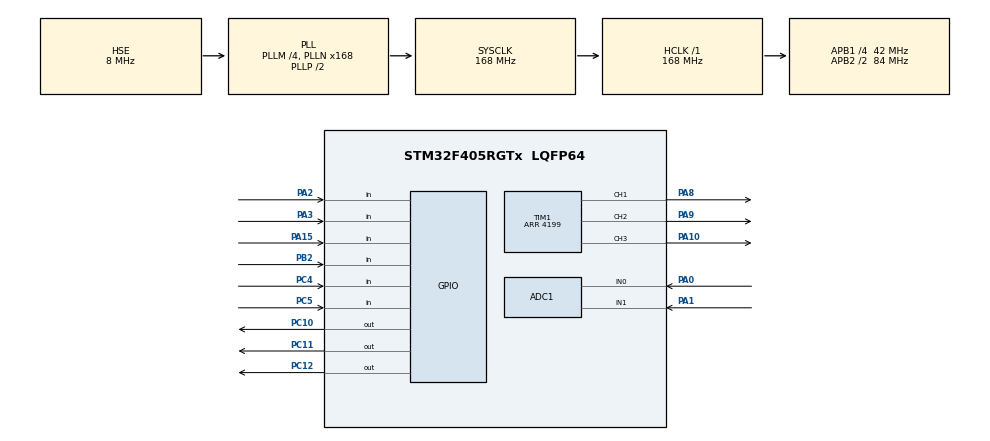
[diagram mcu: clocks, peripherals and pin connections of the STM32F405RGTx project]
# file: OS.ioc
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ADC1.Channel-0\#ChannelRegularConversion=ADC_CHANNEL_0
ADC1.Channel-1\#ChannelRegularConversion=ADC_CHANNEL_1
ADC1.DMAContinuousRequests=ENABLE
ADC1.EOCSelection=ADC_EOC_SEQ_CONV
ADC1.ExternalTrigConv=ADC_EXTERNALTRIGCONV_T4_CC4
ADC1.InjNumberOfConversion=0
ADC1.NbrOfConversion=2
ADC1.NbrOfConversionFlag=1
ADC1.Rank-0\#ChannelRegularConversion=1
ADC1.Rank-1\#ChannelRegularConversion=2
ADC1.SamplingTime-0\#ChannelRegularConversion=ADC_SAMPLETIME_56CYCLES
ADC1.SamplingTime-1\#ChannelRegularConversion=ADC_SAMPLETIME_56CYCLES
ADC1.ScanConvMode=ENABLE
ADC1.master=1
Dma.ADC1.0.Direction=DMA_PERIPH_TO_MEMORY
Dma.ADC1.0.FIFOMode=DMA_FIFOMODE_DISABLE
Dma.ADC1.0.Instance=DMA2_Stream0
Dma.ADC1.0.MemDataAlignment=DMA_MDATAALIGN_WORD
Dma.ADC1.0.MemInc=DMA_MINC_ENABLE
Dma.ADC1.0.Mode=DMA_CIRCULAR
Dma.ADC1.0.PeriphDataAlignment=DMA_PDATAALIGN_WORD
Dma.ADC1.0.PeriphInc=DMA_PINC_DISABLE
Dma.ADC1.0.Priority=DMA_PRIORITY_LOW
Dma.Request0=ADC1
Mcu.Family=STM32F4
Mcu.Name=STM32F405RGTx
Mcu.Package=LQFP64
NVIC.DMA2_Stream0_IRQn=true\:0\:0\:false\:false\:true\:false
NVIC.PriorityGroup=NVIC_PRIORITYGROUP_4
NVIC.TIM1_UP_TIM10_IRQn=true\:0\:0\:false\:false\:true\:true
PA0-WKUP.Signal=ADCx_IN0
PA1.Signal=ADCx_IN1
PA10.Signal=S_TIM1_CH3
PA15.GPIO_PuPd=GPIO_PULLUP
PA15.Signal=GPIO_Input
PA2.GPIO_PuPd=GPIO_PULLUP
PA2.Signal=GPIO_Input
PA3.GPIO_PuPd=GPIO_PULLUP
PA3.Signal=GPIO_Input
PA8.Signal=S_TIM1_CH1
PA9.Signal=S_TIM1_CH2
PB2.GPIO_PuPd=GPIO_PULLUP
PB2.Signal=GPIO_Input
PC10.Signal=GPIO_Output
PC11.Signal=GPIO_Output
PC12.Signal=GPIO_Output
PC14-OSC32_IN.Mode=LSE-External-Oscillator
PC14-OSC32_IN.Signal=RCC_OSC32_IN
PC15-OSC32_OUT.Mode=LSE-External-Oscillator
PC15-OSC32_OUT.Signal=RCC_OSC32_OUT
PC4.GPIO_PuPd=GPIO_PULLUP
PC4.Signal=GPIO_Input
PC5.GPIO_PuPd=GPIO_PULLUP
PC5.Signal=GPIO_Input
PH0-OSC_IN.Mode=HSE-External-Oscillator
PH0-OSC_IN.Signal=RCC_OSC_IN
PH1-OSC_OUT.Mode=HSE-External-Oscillator
PH1-OSC_OUT.Signal=RCC_OSC_OUT
ProjectManager.HeapSize=0x200
ProjectManager.StackSize=0x400
ProjectManager.TargetToolchain=MDK-ARM V5
RCC.48MHZClocksFreq_Value=84000000
RCC.AHBFreq_Value=168000000
RCC.APB1CLKDivider=RCC_HCLK_DIV4
RCC.APB1Freq_Value=42000000
RCC.APB1TimFreq_Value=84000000
RCC.APB2CLKDivider=RCC_HCLK_DIV2
RCC.APB2Freq_Value=84000000
RCC.APB2TimFreq_Value=168000000
RCC.CortexFreq_Value=168000000
RCC.HCLKFreq_Value=168000000
RCC.HSE_VALUE=8000000
RCC.HSI_VALUE=16000000
RCC.PLLM=4
RCC.PLLN=168
RCC.PLLSourceVirtual=RCC_PLLSOURCE_HSE
RCC.SYSCLKFreq_VALUE=168000000
RCC.SYSCLKSource=RCC_SYSCLKSOURCE_PLLCLK
RCC.VCOOutputFreq_Value=336000000
SH.ADCx_IN0.0=ADC1_IN0,IN0
SH.ADCx_IN1.0=ADC1_IN1,IN1
SH.S_TIM1_CH1.0=TIM1_CH1,PWM Generation1 CH1
SH.S_TIM1_CH2.0=TIM1_CH2,PWM Generation2 CH2
SH.S_TIM1_CH3.0=TIM1_CH3,PWM Generation3 CH3
TIM1.Channel-PWM\ Generation1\ CH1=TIM_CHANNEL_1
TIM1.Channel-PWM\ Generation2\ CH2=TIM_CHANNEL_2
TIM1.Channel-PWM\ Generation3\ CH3=TIM_CHANNEL_3
TIM1.Period=4199
TIM1.Pulse-PWM\ Generation1\ CH1=2100
TIM4.Channel-PWM\ Generation4\ No\ Output=TIM_CHANNEL_4
TIM4.Period=840-1
TIM4.Pulse-PWM\ Generation4\ No\ Output=840/2
VP_RTC_VS_RTC_Activate.Mode=RTC_Enabled
VP_TIM1_VS_ClockSourceINT.Mode=Internal
VP_TIM4_VS_ClockSourceINT.Mode=Internal
VP_TIM4_VS_no_output4.Mode=PWM Generation4 No Output
board=custom

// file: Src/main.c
/* USER CODE BEGIN Header */
/**
  ******************************************************************************
  * @file           : main.c
  * @brief          : Main program body
  ******************************************************************************
  ** This notice applies to any and all portions of this file
  * that are not between comment pairs USER CODE BEGIN and
  * USER CODE END. Other portions of this file, whether
  * inserted by the user or by software development tools
  * are owned by their respective copyright owners.
  *
  * COPYRIGHT(c) 2019 STMicroelectronics
  *
  * Redistribution and use in source and binary forms, with or without modification,
  * are permitted provided that the following conditions are met:
  *   1. Redistributions of source code must retain the above copyright notice,
  *      this list of conditions and the following disclaimer.
  *   2. Redistributions in binary form must reproduce the above copyright notice,
  *      this list of conditions and the following disclaimer in the documentation
  *      and/or other materials provided with the distribution.
  *   3. Neither the name of STMicroelectronics nor the names of its contributors
  *      may be used to endorse or promote products derived from this software
  *      without specific prior written permission.
  *
  * THIS SOFTWARE IS PROVIDED BY THE COPYRIGHT HOLDERS AND CONTRIBUTORS "AS IS"
  * AND ANY EXPRESS OR IMPLIED WARRANTIES, INCLUDING, BUT NOT LIMITED TO, THE
  * IMPLIED WARRANTIES OF MERCHANTABILITY AND FITNESS FOR A PARTICULAR PURPOSE ARE
  * DISCLAIMED. IN NO EVENT SHALL THE COPYRIGHT HOLDER OR CONTRIBUTORS BE LIABLE
  * FOR ANY DIRECT, INDIRECT, INCIDENTAL, SPECIAL, EXEMPLARY, OR CONSEQUENTIAL
  * DAMAGES (INCLUDING, BUT NOT LIMITED TO, PROCUREMENT OF SUBSTITUTE GOODS OR
  * SERVICES; LOSS OF USE, DATA, OR PROFITS; OR BUSINESS INTERRUPTION) HOWEVER
  * CAUSED AND ON ANY THEORY OF LIABILITY, WHETHER IN CONTRACT, STRICT LIABILITY,
  * OR TORT (INCLUDING NEGLIGENCE OR OTHERWISE) ARISING IN ANY WAY OUT OF THE USE
  * OF THIS SOFTWARE, EVEN IF ADVISED OF THE POSSIBILITY OF SUCH DAMAGE.
  *
  ******************************************************************************
  */
/* USER CODE END Header */

#include "main.h"

/* USER CODE BEGIN Includes */
#include "includes.h"
/* USER CODE END Includes */

ADC_HandleTypeDef hadc1;
DMA_HandleTypeDef hdma_adc1;

RTC_HandleTypeDef hrtc;

TIM_HandleTypeDef htim1;
TIM_HandleTypeDef htim4;

void SystemClock_Config(void);
static void MX_GPIO_Init(void);
static void MX_DMA_Init(void);
static void MX_RTC_Init(void);
static void MX_TIM1_Init(void);
static void MX_ADC1_Init(void);
static void MX_TIM4_Init(void);

/* USER CODE BEGIN 0 */
unsigned char err=0;
/* USER CODE END 0 */

int main(void)
{
  /* USER CODE BEGIN 1 */
	OS_I_DisAll();
  /* USER CODE END 1 */

  /* MCU Configuration--------------------------------------------------------*/

  /* Reset of all peripherals, Initializes the Flash interface and the Systick. */
  HAL_Init();

  /* Configure the system clock */
  SystemClock_Config();

  /* Initialize all configured peripherals */
  MX_GPIO_Init();
  MX_DMA_Init();
  MX_RTC_Init();
  MX_TIM1_Init();
  MX_ADC1_Init();
  MX_TIM4_Init();
  /* USER CODE BEGIN 2 */
	HAL_TIM_PWM_Start(&htim1, TIM_CHANNEL_1);
	HAL_TIM_Base_Start_IT(&htim1);

	HAL_TIM_PWM_Start(&htim4, TIM_CHANNEL_4);

	HAL_ADC_Start(&hadc1);
	HAL_ADC_Start_DMA(&hadc1, (uint32_t*)&g_adc_raw, countof(g_adc_raw));

	OSInit();
	err |= PR_KEY_Init();
	err |= PR_ADC_Init();
	err |= PR_PWM_Init();
	while(err)
	{

	}
	OSStartTask();

  /* USER CODE END 2 */

  /* Infinite loop */
  while (1)
  {

  }
}

void SystemClock_Config(void)
{
  RCC_OscInitTypeDef RCC_OscInitStruct = {0};
  RCC_ClkInitTypeDef RCC_ClkInitStruct = {0};
  RCC_PeriphCLKInitTypeDef PeriphClkInitStruct = {0};

  /**Configure the main internal regulator output voltage
  */
  __HAL_RCC_PWR_CLK_ENABLE();
  __HAL_PWR_VOLTAGESCALING_CONFIG(PWR_REGULATOR_VOLTAGE_SCALE1);
  /**Initializes the CPU, AHB and APB busses clocks
  */
  RCC_OscInitStruct.OscillatorType = RCC_OSCILLATORTYPE_LSI|RCC_OSCILLATORTYPE_HSE;
  RCC_OscInitStruct.HSEState = RCC_HSE_ON;
  RCC_OscInitStruct.LSIState = RCC_LSI_ON;
  RCC_OscInitStruct.PLL.PLLState = RCC_PLL_ON;
  RCC_OscInitStruct.PLL.PLLSource = RCC_PLLSOURCE_HSE;
  RCC_OscInitStruct.PLL.PLLM = 4;
  RCC_OscInitStruct.PLL.PLLN = 168;
  RCC_OscInitStruct.PLL.PLLP = RCC_PLLP_DIV2;
  RCC_OscInitStruct.PLL.PLLQ = 4;
  if (HAL_RCC_OscConfig(&RCC_OscInitStruct) != HAL_OK)
  {
    Error_Handler();
  }
  /**Initializes the CPU, AHB and APB busses clocks
  */
  RCC_ClkInitStruct.ClockType = RCC_CLOCKTYPE_HCLK|RCC_CLOCKTYPE_SYSCLK
                              |RCC_CLOCKTYPE_PCLK1|RCC_CLOCKTYPE_PCLK2;
  RCC_ClkInitStruct.SYSCLKSource = RCC_SYSCLKSOURCE_PLLCLK;
  RCC_ClkInitStruct.AHBCLKDivider = RCC_SYSCLK_DIV1;
  RCC_ClkInitStruct.APB1CLKDivider = RCC_HCLK_DIV4;
  RCC_ClkInitStruct.APB2CLKDivider = RCC_HCLK_DIV2;

  if (HAL_RCC_ClockConfig(&RCC_ClkInitStruct, FLASH_LATENCY_5) != HAL_OK)
  {
    Error_Handler();
  }
  PeriphClkInitStruct.PeriphClockSelection = RCC_PERIPHCLK_RTC;
  PeriphClkInitStruct.RTCClockSelection = RCC_RTCCLKSOURCE_LSI;
  if (HAL_RCCEx_PeriphCLKConfig(&PeriphClkInitStruct) != HAL_OK)
  {
    Error_Handler();
  }
}

static void MX_ADC1_Init(void)
{

  ADC_ChannelConfTypeDef sConfig = {0};

  /**Configure the global features of the ADC (Clock, Resolution, Data Alignment and number of conversion)
  */
  hadc1.Instance = ADC1;
  hadc1.Init.ClockPrescaler = ADC_CLOCK_SYNC_PCLK_DIV4;
  hadc1.Init.Resolution = ADC_RESOLUTION_12B;
  hadc1.Init.ScanConvMode = ENABLE;
  hadc1.Init.ContinuousConvMode = DISABLE;
  hadc1.Init.DiscontinuousConvMode = DISABLE;
  hadc1.Init.ExternalTrigConvEdge = ADC_EXTERNALTRIGCONVEDGE_RISING;
  hadc1.Init.ExternalTrigConv = ADC_EXTERNALTRIGCONV_T4_CC4;
  hadc1.Init.DataAlign = ADC_DATAALIGN_RIGHT;
  hadc1.Init.NbrOfConversion = 2;
  hadc1.Init.DMAContinuousRequests = ENABLE;
  hadc1.Init.EOCSelection = ADC_EOC_SEQ_CONV;
  if (HAL_ADC_Init(&hadc1) != HAL_OK)
  {
    Error_Handler();
  }
  /**Configure for the selected ADC regular channel its corresponding rank in the sequencer and its sample time.
  */
  sConfig.Channel = ADC_CHANNEL_0;
  sConfig.Rank = 1;
  sConfig.SamplingTime = ADC_SAMPLETIME_56CYCLES;
  if (HAL_ADC_ConfigChannel(&hadc1, &sConfig) != HAL_OK)
  {
    Error_Handler();
  }
  /**Configure for the selected ADC regular channel its corresponding rank in the sequencer and its sample time.
  */
  sConfig.Channel = ADC_CHANNEL_1;
  sConfig.Rank = 2;
  if (HAL_ADC_ConfigChannel(&hadc1, &sConfig) != HAL_OK)
  {
    Error_Handler();
  }

}

static void MX_RTC_Init(void)
{

  /**Initialize RTC Only
  */
  hrtc.Instance = RTC;
  hrtc.Init.HourFormat = RTC_HOURFORMAT_24;
  hrtc.Init.AsynchPrediv = 127;
  hrtc.Init.SynchPrediv = 255;
  hrtc.Init.OutPut = RTC_OUTPUT_DISABLE;
  hrtc.Init.OutPutPolarity = RTC_OUTPUT_POLARITY_HIGH;
  hrtc.Init.OutPutType = RTC_OUTPUT_TYPE_OPENDRAIN;
  if (HAL_RTC_Init(&hrtc) != HAL_OK)
  {
    Error_Handler();
  }

}

static void MX_TIM1_Init(void)
{

  TIM_ClockConfigTypeDef sClockSourceConfig = {0};
  TIM_MasterConfigTypeDef sMasterConfig = {0};
  TIM_OC_InitTypeDef sConfigOC = {0};
  TIM_BreakDeadTimeConfigTypeDef sBreakDeadTimeConfig = {0};

  htim1.Instance = TIM1;
  htim1.Init.Prescaler = 0;
  htim1.Init.CounterMode = TIM_COUNTERMODE_UP;
  htim1.Init.Period = 4199;
  htim1.Init.ClockDivision = TIM_CLOCKDIVISION_DIV1;
  htim1.Init.RepetitionCounter = 0;
  if (HAL_TIM_Base_Init(&htim1) != HAL_OK)
  {
    Error_Handler();
  }
  sClockSourceConfig.ClockSource = TIM_CLOCKSOURCE_INTERNAL;
  if (HAL_TIM_ConfigClockSource(&htim1, &sClockSourceConfig) != HAL_OK)
  {
    Error_Handler();
  }
  if (HAL_TIM_PWM_Init(&htim1) != HAL_OK)
  {
    Error_Handler();
  }
  sMasterConfig.MasterOutputTrigger = TIM_TRGO_RESET;
  sMasterConfig.MasterSlaveMode = TIM_MASTERSLAVEMODE_DISABLE;
  if (HAL_TIMEx_MasterConfigSynchronization(&htim1, &sMasterConfig) != HAL_OK)
  {
    Error_Handler();
  }
  sConfigOC.OCMode = TIM_OCMODE_PWM1;
  sConfigOC.Pulse = 2100;
  sConfigOC.OCPolarity = TIM_OCPOLARITY_HIGH;
  sConfigOC.OCNPolarity = TIM_OCNPOLARITY_HIGH;
  sConfigOC.OCFastMode = TIM_OCFAST_DISABLE;
  sConfigOC.OCIdleState = TIM_OCIDLESTATE_RESET;
  sConfigOC.OCNIdleState = TIM_OCNIDLESTATE_RESET;
  if (HAL_TIM_PWM_ConfigChannel(&htim1, &sConfigOC, TIM_CHANNEL_1) != HAL_OK)
  {
    Error_Handler();
  }
  sConfigOC.Pulse = 0;
  if (HAL_TIM_PWM_ConfigChannel(&htim1, &sConfigOC, TIM_CHANNEL_2) != HAL_OK)
  {
    Error_Handler();
  }
  if (HAL_TIM_PWM_ConfigChannel(&htim1, &sConfigOC, TIM_CHANNEL_3) != HAL_OK)
  {
    Error_Handler();
  }
  sBreakDeadTimeConfig.OffStateRunMode = TIM_OSSR_DISABLE;
  sBreakDeadTimeConfig.OffStateIDLEMode = TIM_OSSI_DISABLE;
  sBreakDeadTimeConfig.LockLevel = TIM_LOCKLEVEL_OFF;
  sBreakDeadTimeConfig.DeadTime = 0;
  sBreakDeadTimeConfig.BreakState = TIM_BREAK_DISABLE;
  sBreakDeadTimeConfig.BreakPolarity = TIM_BREAKPOLARITY_HIGH;
  sBreakDeadTimeConfig.AutomaticOutput = TIM_AUTOMATICOUTPUT_DISABLE;
  if (HAL_TIMEx_ConfigBreakDeadTime(&htim1, &sBreakDeadTimeConfig) != HAL_OK)
  {
    Error_Handler();
  }
  HAL_TIM_MspPostInit(&htim1);

}

static void MX_TIM4_Init(void)
{

  TIM_ClockConfigTypeDef sClockSourceConfig = {0};
  TIM_MasterConfigTypeDef sMasterConfig = {0};
  TIM_OC_InitTypeDef sConfigOC = {0};

  htim4.Instance = TIM4;
  htim4.Init.Prescaler = 0;
  htim4.Init.CounterMode = TIM_COUNTERMODE_UP;
  htim4.Init.Period = 840-1;
  htim4.Init.ClockDivision = TIM_CLOCKDIVISION_DIV1;
  if (HAL_TIM_Base_Init(&htim4) != HAL_OK)
  {
    Error_Handler();
  }
  sClockSourceConfig.ClockSource = TIM_CLOCKSOURCE_INTERNAL;
  if (HAL_TIM_ConfigClockSource(&htim4, &sClockSourceConfig) != HAL_OK)
  {
    Error_Handler();
  }
  if (HAL_TIM_PWM_Init(&htim4) != HAL_OK)
  {
    Error_Handler();
  }
  sMasterConfig.MasterOutputTrigger = TIM_TRGO_RESET;
  sMasterConfig.MasterSlaveMode = TIM_MASTERSLAVEMODE_DISABLE;
  if (HAL_TIMEx_MasterConfigSynchronization(&htim4, &sMasterConfig) != HAL_OK)
  {
    Error_Handler();
  }
  sConfigOC.OCMode = TIM_OCMODE_PWM1;
  sConfigOC.Pulse = 840/2;
  sConfigOC.OCPolarity = TIM_OCPOLARITY_HIGH;
  sConfigOC.OCFastMode = TIM_OCFAST_DISABLE;
  if (HAL_TIM_PWM_ConfigChannel(&htim4, &sConfigOC, TIM_CHANNEL_4) != HAL_OK)
  {
    Error_Handler();
  }

}

static void MX_DMA_Init(void)
{
  /* DMA controller clock enable */
  __HAL_RCC_DMA2_CLK_ENABLE();

  /* DMA interrupt init */
  /* DMA2_Stream0_IRQn interrupt configuration */
  HAL_NVIC_SetPriority(DMA2_Stream0_IRQn, 0, 0);
  HAL_NVIC_EnableIRQ(DMA2_Stream0_IRQn);

}

static void MX_GPIO_Init(void)
{
  GPIO_InitTypeDef GPIO_InitStruct = {0};

  /* GPIO Ports Clock Enable */
  __HAL_RCC_GPIOC_CLK_ENABLE();
  __HAL_RCC_GPIOH_CLK_ENABLE();
  __HAL_RCC_GPIOA_CLK_ENABLE();
  __HAL_RCC_GPIOB_CLK_ENABLE();

  /*Configure GPIO pin Output Level */
  HAL_GPIO_WritePin(GPIOC, GPIO_PIN_10|GPIO_PIN_11|GPIO_PIN_12, GPIO_PIN_RESET);

  /*Configure GPIO pins : PA2 PA3 PA15 */
  GPIO_InitStruct.Pin = GPIO_PIN_2|GPIO_PIN_3|GPIO_PIN_15;
  GPIO_InitStruct.Mode = GPIO_MODE_INPUT;
  GPIO_InitStruct.Pull = GPIO_PULLUP;
  HAL_GPIO_Init(GPIOA, &GPIO_InitStruct);

  /*Configure GPIO pins : PC4 PC5 */
  GPIO_InitStruct.Pin = GPIO_PIN_4|GPIO_PIN_5;
  GPIO_InitStruct.Mode = GPIO_MODE_INPUT;
  GPIO_InitStruct.Pull = GPIO_PULLUP;
  HAL_GPIO_Init(GPIOC, &GPIO_InitStruct);

  /*Configure GPIO pin : PB2 */
  GPIO_InitStruct.Pin = GPIO_PIN_2;
  GPIO_InitStruct.Mode = GPIO_MODE_INPUT;
  GPIO_InitStruct.Pull = GPIO_PULLUP;
  HAL_GPIO_Init(GPIOB, &GPIO_InitStruct);

  /*Configure GPIO pins : PC10 PC11 PC12 */
  GPIO_InitStruct.Pin = GPIO_PIN_10|GPIO_PIN_11|GPIO_PIN_12;
  GPIO_InitStruct.Mode = GPIO_MODE_OUTPUT_PP;
  GPIO_InitStruct.Pull = GPIO_NOPULL;
  GPIO_InitStruct.Speed = GPIO_SPEED_FREQ_LOW;
  HAL_GPIO_Init(GPIOC, &GPIO_InitStruct);

}

void Error_Handler(void)
{
}

/************************ (C) COPYRIGHT STMicroelectronics *****END OF FILE****/
